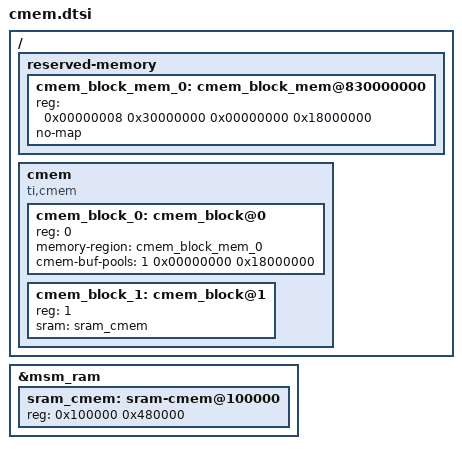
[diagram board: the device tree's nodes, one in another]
/ {
	reserved-memory {

		cmem_block_mem_0: cmem_block_mem@830000000 {
			reg = <0x00000008 0x30000000 0x00000000 0x18000000>;
			no-map;
			status = "okay";
		};
	};

	cmem {
		compatible = "ti,cmem";
		#address-cells = <1>;
		#size-cells = <0>;

		#pool-size-cells = <2>;

		status = "okay";

		cmem_block_0: cmem_block@0 {
			reg = <0>;
			memory-region = <&cmem_block_mem_0>;
			cmem-buf-pools = <1 0x00000000 0x18000000>;
		};

		cmem_block_1: cmem_block@1 {
			reg = <1>;
			sram = <&sram_cmem>;
		};
	};
};

&msm_ram {
	sram_cmem: sram-cmem@100000 {
		reg = <0x100000 0x480000>;
	};
};
